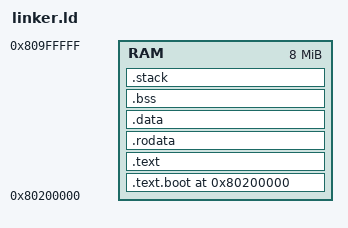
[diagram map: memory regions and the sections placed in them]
/*-------------------
<human-generated>
This code was generated by a tool (a human, me).
Changes to this file may cause correct behavior if the code is rewritten by a robot.
</human-generated>
--------------------*/
OUTPUT_ARCH(riscv)
ENTRY(_start)

MEMORY {
    RAM : ORIGIN = 0x80200000, LENGTH = 8M
}

SECTIONS {
    . = ORIGIN(RAM);
    _image_start = .;

    .text.boot : {
        *(.text.boot)
    } > RAM

    .text : {
        *(.text .text.*)
    } > RAM

    .rodata : ALIGN(4096) {
        *(.rodata .rodata.*)
    } > RAM

    .data : ALIGN(4096) {
        *(.data .data.*)
    } > RAM

    .bss (NOLOAD) : ALIGN(4096) {
        _bss_start = .;
        *(.bss .bss.*)
        *(COMMON)
        _bss_end = .;
    } > RAM

    .stack (NOLOAD) : ALIGN(16) {
        _stack_bottom = .;
        . += 0x2000;
         _stack_top = .;
    } > RAM /* 8KB, stack grows down from top */

    _image_end = .;
}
